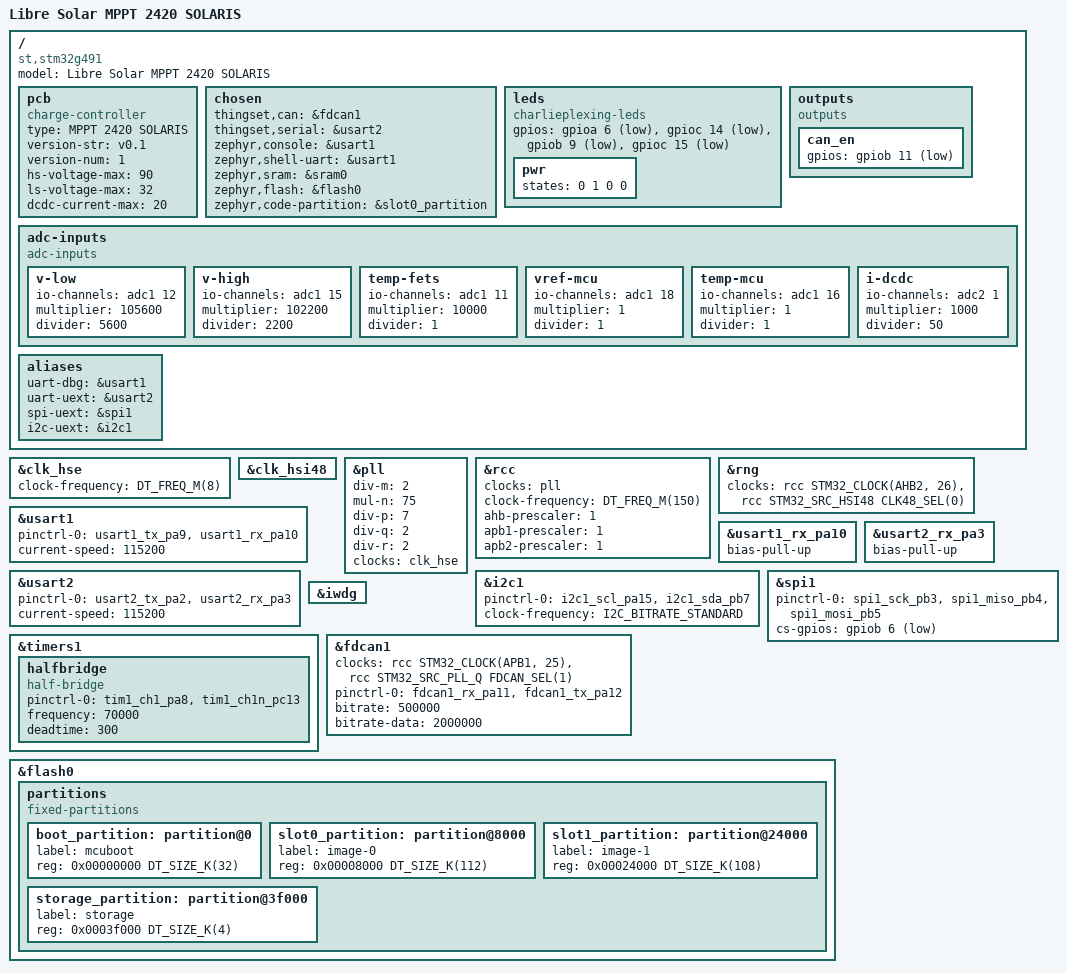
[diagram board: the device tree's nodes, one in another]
/*
 * Copyright (c) The Libre Solar Project Contributors
 *
 * SPDX-License-Identifier: Apache-2.0
 */

/dts-v1/;
#include <st/g4/stm32g491Xc.dtsi>
#include <st/g4/stm32g491c(c-e)tx-pinctrl.dtsi>

/ {
	model = "Libre Solar MPPT 2420 SOLARIS";
	compatible = "st,stm32g491";

	pcb {
		compatible = "charge-controller";

		type = "MPPT 2420 SOLARIS";
		version-str = "v0.1";
		version-num = <1>;

		hs-voltage-max = <90>;
		ls-voltage-max = <32>;
		dcdc-current-max = <20>;
	};

	chosen {
		thingset,can = &fdcan1;
		thingset,serial = &usart2;
		zephyr,console = &usart1;
		zephyr,shell-uart = &usart1;
		zephyr,sram = &sram0;
		zephyr,flash = &flash0;
		zephyr,code-partition = &slot0_partition;
	};

	/* temporary solution only using green color LED */
	leds {
		compatible = "charlieplexing-leds";
		gpios = <&gpioa 6 GPIO_ACTIVE_LOW>,	/* chg red */
			<&gpioc 14 GPIO_ACTIVE_LOW>,	/* chg green */
			<&gpiob 9 GPIO_ACTIVE_LOW>,	/* dis red */
			<&gpioc 15 GPIO_ACTIVE_LOW>;	/* dis green */

		pwr {
			states = <0 1 0 0>;
		};
	};

	outputs {
		compatible = "outputs";

		can_en {
			gpios = <&gpiob 11 GPIO_ACTIVE_LOW>;
		};
	};

	adc-inputs {
		compatible = "adc-inputs";

		v-low {
			io-channels = <&adc1 12>;
			multiplier = <105600>;
			divider = <5600>;
		};

		v-high {
			io-channels = <&adc1 15>;
			multiplier = <102200>;
			divider = <2200>;
		};

		temp-fets {
			io-channels = <&adc1 11>;
			multiplier = <10000>;	// 10k NTC series resistor
			divider = <1>;
		};

		vref-mcu {
			io-channels = <&adc1 18>;
			multiplier = <1>;
			divider = <1>;
		};

		temp-mcu {
			io-channels = <&adc1 16>;
			multiplier = <1>;
			divider = <1>;
		};

		i-dcdc {
			io-channels = <&adc2 1>;
			// amp gain: 25, resistor: 2 mOhm
			multiplier = <1000>;	// 1000
			divider = <50>;	// 2*25
		};
	};

	aliases {
		uart-dbg = &usart1;
		uart-uext = &usart2;
		spi-uext = &spi1;
		i2c-uext = &i2c1;
	};
};

&clk_hse {
	clock-frequency = <DT_FREQ_M(8)>;
	status = "okay";
};

&clk_hsi48 {
	status = "okay";
};

&pll {
	div-m = <2>;
	mul-n = <75>;
	div-p = <7>;
	div-q = <2>;
	div-r = <2>;
	clocks = <&clk_hse>;
	status = "okay";
};

&rcc {
	clocks = <&pll>;
	clock-frequency = <DT_FREQ_M(150)>;
	ahb-prescaler = <1>;
	apb1-prescaler = <1>;
	apb2-prescaler = <1>;
};

&rng {
	clocks = <&rcc STM32_CLOCK(AHB2, 26)>,
		 <&rcc STM32_SRC_HSI48 CLK48_SEL(0)>;
	status = "okay";
};

&usart1 {
	pinctrl-0 = <&usart1_tx_pa9 &usart1_rx_pa10>;
	pinctrl-names = "default";
	current-speed = <115200>;
	status = "okay";
};

&usart1_rx_pa10 {
	bias-pull-up;	// avoid junk characters if pin is left floating
};

&usart2 {
	pinctrl-0 = <&usart2_tx_pa2 &usart2_rx_pa3>;
	pinctrl-names = "default";
	current-speed = <115200>;
	status = "okay";
};

&usart2_rx_pa3 {
	bias-pull-up;	// avoid junk characters if pin is left floating
};

&i2c1 {
	pinctrl-0 = <&i2c1_scl_pa15 &i2c1_sda_pb7>;
	pinctrl-names = "default";
	clock-frequency = <I2C_BITRATE_STANDARD>;
	status = "okay";
};

&spi1 {
	pinctrl-0 = <&spi1_sck_pb3 &spi1_miso_pb4 &spi1_mosi_pb5>;
	pinctrl-names = "default";
	cs-gpios = <&gpiob 6 GPIO_ACTIVE_LOW>;
	status = "okay";
};

&iwdg {
	status = "okay";
};

&timers1 {
	status = "okay";

	halfbridge: halfbridge {
		compatible = "half-bridge";
		pinctrl-0 = <&tim1_ch1_pa8 &tim1_ch1n_pc13>;
		pinctrl-names = "default";
		frequency = <70000>;
		deadtime = <300>;
	};
};

&fdcan1 {
	clocks = <&rcc STM32_CLOCK(APB1, 25)>,
		 <&rcc STM32_SRC_PLL_Q FDCAN_SEL(1)>;
	pinctrl-0 = <&fdcan1_rx_pa11 &fdcan1_tx_pa12>;
	pinctrl-names = "default";
	bitrate = <500000>;
	bitrate-data = <2000000>;
	status = "okay";
};

/*
 * Below partition layout allows to use MCUboot if CONFIG_BOOTLOADER_MCUBOOT is enabled. Otherwise,
 * the code will just use the entire available flash of the MCU.
 */
&flash0 {
	partitions {
		compatible = "fixed-partitions";
		#address-cells = <1>;
		#size-cells = <1>;

		boot_partition: partition@0 {
			label = "mcuboot";
			reg = <0x00000000 DT_SIZE_K(32)>;
		};

		slot0_partition: partition@8000 {
			label = "image-0";
			reg = <0x00008000 DT_SIZE_K(112)>;
		};

		slot1_partition: partition@24000 {
			label = "image-1";
			reg = <0x00024000 DT_SIZE_K(108)>;
		};

		/* Set 4Kb of storage at the end of the 256Kb of flash */
		storage_partition: partition@3f000 {
			label = "storage";
			reg = <0x0003f000 DT_SIZE_K(4)>;
		};
	};
};
